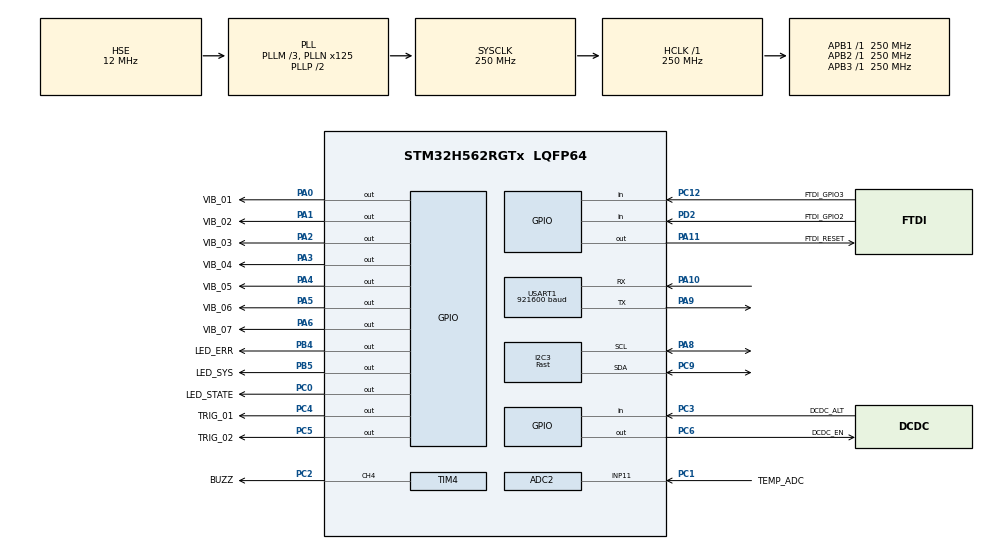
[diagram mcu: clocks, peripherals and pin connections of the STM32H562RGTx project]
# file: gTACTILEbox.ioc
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ADC2.Channel-0\#ChannelRegularConversion=ADC_CHANNEL_11
ADC2.MonitoredBy-0\#ChannelRegularConversion=__NULL
ADC2.NbrOfConversionFlag=1
ADC2.OffsetNumber-0\#ChannelRegularConversion=ADC_OFFSET_NONE
ADC2.Rank-0\#ChannelRegularConversion=1
ADC2.SamplingTime-0\#ChannelRegularConversion=ADC_SAMPLETIME_24CYCLES_5
BOOTPATH.BootPathName=LEGACY
BOOTPATH.UserSelectedBootPath=LEGACY
CORTEX_M33_NS.AccessPermission-Cortex_Memory_Protection_Unit_Region0_Settings=MPU_REGION_PRIV_RO
CORTEX_M33_NS.AllocateAttribute-Cortex_Memory_Protection_Unit_Region0_Settings=MPU_R_ALLOCATE
CORTEX_M33_NS.AllocateAttribute-Cortex_Memory_Protection_Unit_Region1_Settings=MPU_RW_ALLOCATE
CORTEX_M33_NS.AttributesIndex-Cortex_Memory_Protection_Unit_Region1_Settings=MPU_ATTRIBUTES_NUMBER1
CORTEX_M33_NS.BaseAddress-Cortex_Memory_Protection_Unit_Region0_Settings=0x08000000
CORTEX_M33_NS.BaseAddress-Cortex_Memory_Protection_Unit_Region1_Settings=0x20000000
CORTEX_M33_NS.CacheableAttribute-Cortex_Memory_Protection_Unit_Region1_Settings=MPU_WRITE_BACK
CORTEX_M33_NS.Enable-Cortex_Memory_Protection_Unit_Region0_Settings=MPU_REGION_ENABLE
CORTEX_M33_NS.Enable-Cortex_Memory_Protection_Unit_Region1_Settings=MPU_REGION_ENABLE
CORTEX_M33_NS.LimitAddress-Cortex_Memory_Protection_Unit_Region0_Settings=0x080FFFFF
CORTEX_M33_NS.LimitAddress-Cortex_Memory_Protection_Unit_Region1_Settings=0x2009FFFF
CORTEX_M33_NS.MPU_Control=__NULL
CORTEX_M33_NS.Number-Cortex_Memory_Protection_Unit_Region1_Settings=MPU_REGION_NUMBER1
CORTEX_M33_NS.userName=CORTEX_M33
GPDMA1.DESTINC_GPDMACH7=DMA_DINC_INCREMENTED
GPDMA1.DIRECTION_GPDMACH6=DMA_MEMORY_TO_PERIPH
GPDMA1.IPHANDLE_GPDMACH6-SIMPLEREQUEST_GPDMACH6=__NULL
GPDMA1.IPHANDLE_GPDMACH7-SIMPLEREQUEST_GPDMACH7=__NULL
GPDMA1.REQUEST_GPDMACH6=GPDMA1_REQUEST_USART1_TX
GPDMA1.REQUEST_GPDMACH7=GPDMA1_REQUEST_USART1_RX
GPDMA1.SRCINC_GPDMACH6=DMA_SINC_INCREMENTED
GTZC.MPCBB1_Area_Privilege=GTZC_MPCBB_REGION_NPRIV
GTZC.MPCBB1_Area_Privilege_Choice=from full Privileged
GTZC.MPCBB1_SecConfig_array=00000000\:00000000\:00000000\:00000000\:00000000\:00000000\:00000000\:00000000\:00000000\:00000000\:00000000\:00000000\:00000000\:00000000\:00000000\:00000000
GTZC.MPCBB2_Area_Privilege=GTZC_MPCBB_REGION_NPRIV
GTZC.MPCBB2_Area_Privilege_Choice=from full Privileged
GTZC.MPCBB2_SecConfig_array=00000000\:00000000\:00000000\:00000000
GTZC.MPCBB3_Area_Privilege=GTZC_MPCBB_REGION_NPRIV
GTZC.MPCBB3_Area_Privilege_Choice=from full Privileged
GTZC.MPCBB3_SecConfig_array=00000000\:00000000\:00000000\:00000000\:00000000\:00000000\:00000000\:00000000\:00000000\:00000000\:00000000\:00000000\:00000000\:00000000\:00000000\:00000000\:00000000\:00000000\:00000000\:00000000
I2C3.I2C_Speed_Mode=I2C_Fast
I2C3.Timing=0x10C043E5
IWDG.Prescaler=IWDG_PRESCALER_8
Mcu.Family=STM32H5
Mcu.Name=STM32H562RGTx
Mcu.Package=LQFP64
NVIC.GPDMA1_Channel6_IRQn=true\:2\:0\:true\:false\:true\:false\:true\:true
NVIC.GPDMA1_Channel7_IRQn=true\:3\:0\:true\:false\:true\:false\:true\:true
NVIC.PriorityGroup=NVIC_PRIORITYGROUP_4
NVIC.RCC_IRQn=true\:0\:0\:false\:false\:true\:true\:false\:true
NVIC.USART1_IRQn=true\:1\:0\:true\:false\:true\:false\:true\:true
PA0.GPIO_Label=VIB_01
PA0.Signal=GPIO_Output
PA1.GPIO_Label=VIB_02
PA1.Signal=GPIO_Output
PA10.Mode=Asynchronous
PA10.Signal=USART1_RX
PA11.GPIO_Label=FTDI_RESET
PA11.GPIO_ModeDefaultOutputPP=GPIO_MODE_OUTPUT_OD
PA11.GPIO_PuPd=GPIO_NOPULL
PA11.PinState=GPIO_PIN_SET
PA11.Signal=GPIO_Output
PA13(JTMS/SWDIO).Mode=Trace_Asynchronous_SW
PA13(JTMS/SWDIO).Signal=DEBUG_JTMS-SWDIO
PA14(JTCK/SWCLK).Mode=Trace_Asynchronous_SW
PA14(JTCK/SWCLK).Signal=DEBUG_JTCK-SWCLK
PA2.GPIO_Label=VIB_03
PA2.Signal=GPIO_Output
PA3.GPIO_Label=VIB_04
PA3.Signal=GPIO_Output
PA4.GPIO_Label=VIB_05
PA4.Signal=GPIO_Output
PA5.GPIO_Label=VIB_06
PA5.Signal=GPIO_Output
PA6.GPIO_Label=VIB_07
PA6.Signal=GPIO_Output
PA8.Mode=I2C
PA8.Signal=I2C3_SCL
PA9.Mode=Asynchronous
PA9.Signal=USART1_TX
PB3(JTDO/TRACESWO).Mode=Trace_Asynchronous_SW
PB3(JTDO/TRACESWO).Signal=DEBUG_JTDO-SWO
PB4(NJTRST).GPIO_Label=LED_ERR
PB4(NJTRST).PinState=GPIO_PIN_SET
PB4(NJTRST).Signal=GPIO_Output
PB5.GPIO_Label=LED_SYS
PB5.PinState=GPIO_PIN_SET
PB5.Signal=GPIO_Output
PC0.GPIO_Label=LED_STATE
PC0.PinState=GPIO_PIN_SET
PC0.Signal=GPIO_Output
PC1.GPIO_Label=TEMP_ADC
PC1.Signal=ADCx_INP11
PC12.GPIO_Label=FTDI_GPIO3
PC12.GPIO_PuPd=GPIO_PULLDOWN
PC12.Signal=GPIO_Input
PC2.GPIO_Label=BUZZ
PC2.Signal=S_TIM4_CH4
PC3.GPIO_Label=DCDC_ALT
PC3.Signal=GPIO_Input
PC4.GPIO_Label=TRIG_01
PC4.Signal=GPIO_Output
PC5.GPIO_Label=TRIG_02
PC5.Signal=GPIO_Output
PC6.GPIO_Label=DCDC_EN
PC6.Signal=GPIO_Output
PC9.Mode=I2C
PC9.Signal=I2C3_SDA
PD2.GPIO_Label=FTDI_GPIO2
PD2.GPIO_PuPd=GPIO_PULLDOWN
PD2.Signal=GPIO_Input
PH0-OSC_IN(PH0).Mode=HSE-External-Oscillator
PH0-OSC_IN(PH0).Signal=RCC_OSC_IN
PH1-OSC_OUT(PH1).Mode=HSE-External-Oscillator
PH1-OSC_OUT(PH1).Signal=RCC_OSC_OUT
ProjectManager.HeapSize=0x2000
ProjectManager.StackSize=0x400
ProjectManager.TargetToolchain=STM32CubeIDE
RCC.ADCCLockSelection=RCC_ADCDACCLKSOURCE_PLL2R
RCC.ADCFreq_Value=64000000
RCC.AHBFreq_Value=250000000
RCC.APB1Freq_Value=250000000
RCC.APB1TimFreq_Value=250000000
RCC.APB2Freq_Value=250000000
RCC.APB2TimFreq_Value=250000000
RCC.APB3Freq_Value=250000000
RCC.CSI_VALUE=4000000
RCC.CortexFreq_Value=250000000
RCC.EPOD_VALUE=12000000
RCC.EnbaleCSS=true
RCC.HCLKFreq_Value=250000000
RCC.HSE_VALUE=12000000
RCC.HSI48_VALUE=48000000
RCC.HSI_VALUE=64000000
RCC.LSE_VALUE=32768
RCC.LSIRC_VALUE=32000
RCC.PLL2FRACN=0
RCC.PLL2M=3
RCC.PLL2N=64
RCC.PLL2R=4
RCC.PLL2Source=RCC_PLL2_SOURCE_HSE
RCC.PLL3FRACN=0
RCC.PLL3M=3
RCC.PLL3N=125
RCC.PLL3Source=RCC_PLL3_SOURCE_HSE
RCC.PLLFRACN=0
RCC.PLLM=3
RCC.PLLN=125
RCC.PLLSourceVirtual=RCC_PLL1_SOURCE_HSE
RCC.SYSCLKFreq_VALUE=250000000
RCC.SYSCLKSource=RCC_SYSCLKSOURCE_PLLCLK
RCC.USBFreq_Value=48000000
RCC.VCOOutputFreq_Value=500000000
SH.ADCx_INP11.0=ADC2_INP11,IN11-Single-Ended
SH.S_TIM4_CH4.0=TIM4_CH4,PWM Generation4 CH4
TIM4.Channel-PWM\ Generation4\ CH4=TIM_CHANNEL_4
TIM4.Prescaler=250-1
USART1.BaudRate=921600
USART1.VirtualMode-Asynchronous=VM_ASYNC
VP_BOOTPATH_VS_BOOTPATH.Mode=BP_Activate
VP_CORTEX_M33_NS_VS_Hclk.Mode=Hclk_Mode
VP_CRC_VS_CRC.Mode=CRC_Activate
VP_GPDMA1_VS_GPDMACH6.Mode=SIMPLEREQUEST_GPDMACH6
VP_GPDMA1_VS_GPDMACH7.Mode=SIMPLEREQUEST_GPDMACH7
VP_GTZC_VS_GTZC_Enable.Mode=GTZC_Enable
VP_ICACHE_VS_ICACHE.Mode=DefaultMode
VP_IWDG_VS_IWDG.Mode=IWDG_Activate
VP_MEMORYMAP_VS_MEMORYMAP.Mode=CurAppReg
VP_PWR_VS_DBSignals.Mode=DisableDeadBatterySignals
VP_PWR_VS_LPOM.Mode=PowerOptimisation
VP_PWR_VS_SECSignals.Mode=Security/Privilege
VP_TIM4_VS_ClockSourceINT.Mode=Internal
VP_gtec.gLib_VS_DriverJjgApp_1.0.0_0.9.18.Mode=DriverJjgApp
VP_gtec.gLib_VS_DriverJjgCore_1.0.0_0.9.18.Mode=DriverJjgCore
board=custom
gtec.gLib.0.9.18.DriverJjgApp=true
gtec.gLib.0.9.18.DriverJjgCore=true

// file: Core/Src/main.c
/* USER CODE BEGIN Header */
/**
  ******************************************************************************
  * @file           : main.c
  * @brief          : Main program body
  ******************************************************************************
  * @attention
  *
  * Copyright (c) 2024 STMicroelectronics.
  * All rights reserved.
  *
  * This software is licensed under terms that can be found in the LICENSE file
  * in the root directory of this software component.
  * If no LICENSE file comes with this software, it is provided AS-IS.
  *
  ******************************************************************************
  */
/* USER CODE END Header */
#include "main.h"
#include "adc.h"
#include "crc.h"
#include "gpdma.h"
#include "gtzc.h"
#include "i2c.h"
#include "icache.h"
#include "iwdg.h"
#include "memorymap.h"
#include "tim.h"
#include "usart.h"
#include "gpio.h"

/* USER CODE BEGIN Includes */
#include "gCore.h"
/* USER CODE END Includes */

void SystemClock_Config(void);

int main(void)
{

  /* USER CODE BEGIN 1 */
	gCorePreInit();
  /* USER CODE END 1 */

  /* MCU Configuration--------------------------------------------------------*/

  /* Reset of all peripherals, Initializes the Flash interface and the Systick. */
  HAL_Init();

  /* Configure the system clock */
  SystemClock_Config();
  /* GTZC initialisation */
  MX_GTZC_Init();

  /* Initialize all configured peripherals */
  MX_GPIO_Init();
  MX_GPDMA1_Init();
  MX_ADC2_Init();
  MX_CRC_Init();
  MX_USART1_UART_Init();
  MX_I2C3_Init();
  MX_ICACHE_Init();
  MX_TIM4_Init();
  MX_IWDG_Init();
  /* USER CODE BEGIN 2 */
  gCoreInit();
  /* USER CODE END 2 */

  /* Infinite loop */
  /* USER CODE BEGIN WHILE */
  while (1)
  {
  	gCoreLoop();
    /* USER CODE END WHILE */

  }
}

void SystemClock_Config(void)
{
  RCC_OscInitTypeDef RCC_OscInitStruct = {0};
  RCC_ClkInitTypeDef RCC_ClkInitStruct = {0};

  /** Configure the main internal regulator output voltage
  */
  __HAL_PWR_VOLTAGESCALING_CONFIG(PWR_REGULATOR_VOLTAGE_SCALE0);

  while(!__HAL_PWR_GET_FLAG(PWR_FLAG_VOSRDY)) {}

  /** Initializes the RCC Oscillators according to the specified parameters
  * in the RCC_OscInitTypeDef structure.
  */
  RCC_OscInitStruct.OscillatorType = RCC_OSCILLATORTYPE_LSI|RCC_OSCILLATORTYPE_HSE;
  RCC_OscInitStruct.HSEState = RCC_HSE_ON;
  RCC_OscInitStruct.LSIState = RCC_LSI_ON;
  RCC_OscInitStruct.PLL.PLLState = RCC_PLL_ON;
  RCC_OscInitStruct.PLL.PLLSource = RCC_PLL1_SOURCE_HSE;
  RCC_OscInitStruct.PLL.PLLM = 3;
  RCC_OscInitStruct.PLL.PLLN = 125;
  RCC_OscInitStruct.PLL.PLLP = 2;
  RCC_OscInitStruct.PLL.PLLQ = 2;
  RCC_OscInitStruct.PLL.PLLR = 2;
  RCC_OscInitStruct.PLL.PLLRGE = RCC_PLL1_VCIRANGE_2;
  RCC_OscInitStruct.PLL.PLLVCOSEL = RCC_PLL1_VCORANGE_WIDE;
  RCC_OscInitStruct.PLL.PLLFRACN = 0;
  if (HAL_RCC_OscConfig(&RCC_OscInitStruct) != HAL_OK)
  {
    Error_Handler();
  }

  /** Initializes the CPU, AHB and APB buses clocks
  */
  RCC_ClkInitStruct.ClockType = RCC_CLOCKTYPE_HCLK|RCC_CLOCKTYPE_SYSCLK
                              |RCC_CLOCKTYPE_PCLK1|RCC_CLOCKTYPE_PCLK2
                              |RCC_CLOCKTYPE_PCLK3;
  RCC_ClkInitStruct.SYSCLKSource = RCC_SYSCLKSOURCE_PLLCLK;
  RCC_ClkInitStruct.AHBCLKDivider = RCC_SYSCLK_DIV1;
  RCC_ClkInitStruct.APB1CLKDivider = RCC_HCLK_DIV1;
  RCC_ClkInitStruct.APB2CLKDivider = RCC_HCLK_DIV1;
  RCC_ClkInitStruct.APB3CLKDivider = RCC_HCLK_DIV1;

  if (HAL_RCC_ClockConfig(&RCC_ClkInitStruct, FLASH_LATENCY_5) != HAL_OK)
  {
    Error_Handler();
  }

  /** Enables the Clock Security System
  */
  HAL_RCC_EnableCSS();

  /** Configure the programming delay
  */
  __HAL_FLASH_SET_PROGRAM_DELAY(FLASH_PROGRAMMING_DELAY_2);
}

void Error_Handler(void)
{
  __disable_irq();
  while (1)
  {
  }
}
